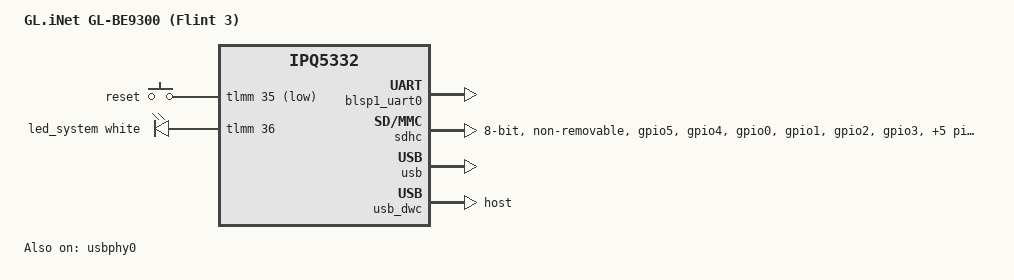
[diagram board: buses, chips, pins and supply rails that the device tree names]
// SPDX-License-Identifier: GPL-2.0-or-later OR MIT
/*
 * GL.iNet Flint 3 (GL-BE9300) WiFi 7 router
 *
 * SoC:     Qualcomm IPQ5332 (4x Cortex-A53)
 * RAM:     1 GiB DDR4
 * Storage: 8 GiB eMMC
 * WiFi:    2.4 GHz integrated (IPQ5332)
 *          5 GHz QCN9274 (PCIe)
 *          6 GHz QCN6274 (PCIe)
 * Eth:     1x 2.5 GbE WAN  (RTL8221B over USXGMII)
 *          4x 2.5 GbE LAN  (QCA8084 quad PHY)
 * USB:     1x USB 3.0
 *
 * STATUS: SCAFFOLD - DO NOT FLASH.
 *
 * This DTS intentionally references only nodes that exist in the
 * upstream Linux 6.12 ipq5332.dtsi (which the OpenWrt kernel pulls in
 * unmodified). The following blocks are deliberately omitted because
 * the kernel-side support does not exist yet:
 *
 *   - MDIO / PHY / PCS / PPE / EDMA (no driver/binding for IPQ5332)
 *   - PCIe controller/PHY DTS nodes (the IPQ5332 PCIe UNIPHY 28LP
 *     driver patch in qualcommax adds driver-level support, but the
 *     SoC dtsi has no pcie* nodes upstream)
 *   - Integrated 2.4 GHz radio (no wifi node upstream)
 *
 * GPIO numbers for the reset button and LEDs are UNVERIFIED placeholders
 * derived from the Wallys / Qualcomm AP-MI01.6 reference layout and
 * sibling GL.iNet devices. They MUST be confirmed against an actual
 * GL-BE9300 via UART boot log + `gpio readall` from a recovery initramfs
 * before the device can be considered usable.
 */

/dts-v1/;

#include "ipq5332.dtsi"

#include <dt-bindings/gpio/gpio.h>
#include <dt-bindings/input/input.h>
#include <dt-bindings/leds/common.h>

/ {
	model = "GL.iNet GL-BE9300 (Flint 3)";
	compatible = "glinet,gl-be9300", "qcom,ipq5332";

	aliases {
		serial0 = &blsp1_uart0;
		led-boot = &led_system;
		led-failsafe = &led_system;
		led-running = &led_system;
		led-upgrade = &led_system;
	};

	chosen {
		stdout-path = "serial0:115200n8";
	};

	keys {
		compatible = "gpio-keys";

		reset {
			label = "reset";
			linux,code = <KEY_RESTART>;
			/* TODO: verify GPIO against hardware - placeholder from AP-MI01.6 ref */
			gpios = <&tlmm 35 GPIO_ACTIVE_LOW>;
			debounce-interval = <60>;
		};
	};

	leds {
		compatible = "gpio-leds";

		led_system: system {
			function = LED_FUNCTION_STATUS;
			color = <LED_COLOR_ID_WHITE>;
			/* TODO: verify GPIO against hardware */
			gpios = <&tlmm 36 GPIO_ACTIVE_HIGH>;
		};
	};
};

&blsp1_uart0 {
	pinctrl-0 = <&serial_0_pins>;
	pinctrl-names = "default";
	status = "okay";
};

&sdhc {
	bus-width = <8>;
	max-frequency = <384000000>;
	mmc-ddr-1_8v;
	mmc-hs200-1_8v;
	mmc-hs400-1_8v;
	mmc-hs400-enhanced-strobe;
	non-removable;
	pinctrl-0 = <&sdc_default_state>;
	pinctrl-names = "default";
	status = "okay";
};

&tlmm {
	sdc_default_state: sdc-default-state {
		clk-pins {
			pins = "gpio5";
			function = "sdc_clk";
			drive-strength = <8>;
			bias-disable;
		};

		cmd-pins {
			pins = "gpio4";
			function = "sdc_cmd";
			drive-strength = <8>;
			bias-pull-up;
		};

		data-pins {
			pins = "gpio0", "gpio1", "gpio2", "gpio3",
			       "gpio6", "gpio7", "gpio8", "gpio9";
			function = "sdc_data";
			drive-strength = <8>;
			bias-pull-up;
		};

		rclk-pins {
			pins = "gpio10";
			function = "sdc_rclk";
			drive-strength = <8>;
			bias-pull-down;
		};
	};
};

&usb {
	status = "okay";
};

&usb_dwc {
	dr_mode = "host";
};

&usbphy0 {
	status = "okay";
};
